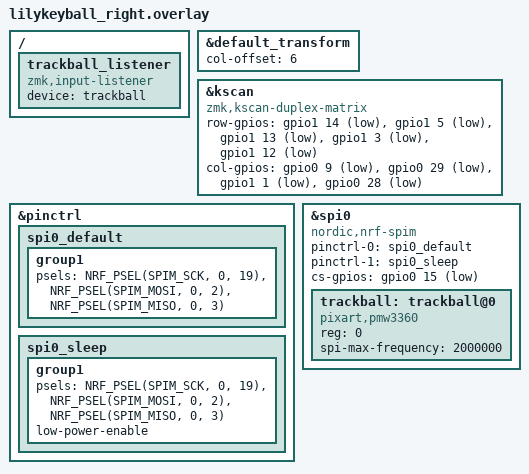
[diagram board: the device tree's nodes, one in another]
// This file was generated from a template. Edit it to match your keyboard.
// See https://zmk.dev/docs/development/hardware-integration/new-shield for more
// instructions.

#include "lilykeyball.dtsi"

&default_transform {
    // Set this to the number of columns on the left side.
    col-offset = <6>;
};

&kscan {
    compatible = "zmk,kscan-duplex-matrix";

    row-gpios
        = <&gpio1 14 GPIO_ACTIVE_LOW>
        , <&gpio1 5  GPIO_ACTIVE_LOW>
        , <&gpio1 13 GPIO_ACTIVE_LOW>
        , <&gpio1 3  GPIO_ACTIVE_LOW>
        , <&gpio1 12 GPIO_ACTIVE_LOW>
        ;

    col-gpios
        = <&gpio0 9  GPIO_ACTIVE_LOW>
        , <&gpio0 29 GPIO_ACTIVE_LOW>
        , <&gpio1 1  GPIO_ACTIVE_LOW>
        , <&gpio0 28 GPIO_ACTIVE_LOW>
        ;
};

&pinctrl {
    spi0_default: spi0_default {
        group1 {
            psels = <NRF_PSEL(SPIM_SCK, 0, 19)>,
                <NRF_PSEL(SPIM_MOSI, 0, 2)>,
                <NRF_PSEL(SPIM_MISO, 0, 3)>;
        };
    };

    spi0_sleep: spi0_sleep {
        group1 {
            psels = <NRF_PSEL(SPIM_SCK, 0, 19)>,
                <NRF_PSEL(SPIM_MOSI, 0, 2)>,
                <NRF_PSEL(SPIM_MISO, 0, 3)>;
            low-power-enable;
        };
    };
};

&spi0 {
    status = "okay";
    compatible = "nordic,nrf-spim";
    pinctrl-0 = <&spi0_default>;
    pinctrl-1 = <&spi0_sleep>;
    pinctrl-names = "default", "sleep";
    cs-gpios = <&gpio0 15 GPIO_ACTIVE_LOW>;

    trackball: trackball@0 {
        status = "okay";
        compatible = "pixart,pmw3360";
        reg = <0>;
        // Use standard 4-wire SPI: CS, SCK, MOSI, MISO.
        // The driver intentionally runs in polling mode, matching the QMK-style logic.
        spi-max-frequency = <2000000>;
    };
};

/ {
  trackball_listener {
    compatible = "zmk,input-listener";
    device = <&trackball>;

  };
};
